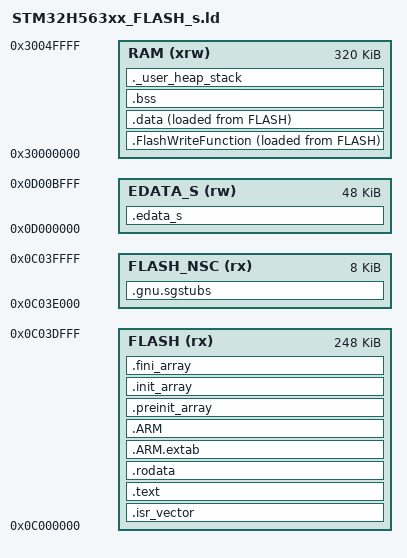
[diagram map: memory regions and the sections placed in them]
/*******************************************************************************
 **
 ** @file        : LinkerScript.ld
 **
 ** @author      : Auto-generated by STM32CubeIDE
 **
 ** @brief       : Linker script for STM32H563xx Device from STM32H5 series
 **                      2048Kbytes FLASH
 **                      640Kbytes RAM
 **
 **                Set heap size, stack size and stack location according
 **                to application requirements.
 **
 **                Set memory bank area and size if external memory is used
 **
 **  Target      : STMicroelectronics STM32
 **
 **  Distribution: The file is distributed as is, without any warranty
 **                of any kind.
 **
 ******************************************************************************
 ** @attention
 **
 ** Copyright (c) 2023 STMicroelectronics.
 ** All rights reserved.
 **
 ** This software is licensed under terms that can be found in the LICENSE file
 ** in the root directory of this software component.
 ** If no LICENSE file comes with this software, it is provided AS-IS.
 **
 ******************************************************************************
 */

/* Entry Point */
ENTRY(Reset_Handler)

/* Highest address of the user mode stack */
_estack = ORIGIN(RAM) + LENGTH(RAM);

_Min_Heap_Size  = 0x200;
_Min_Stack_Size = 0x400;

/* Memories definition */
MEMORY
{
  RAM      (xrw) : ORIGIN = 0x30000000, LENGTH = 320K

  /* Secure firmware code: Bank 1 sectors 0-30 (31 sectors x 8KB = 248KB) */
  FLASH    (rx)  : ORIGIN = 0x0C000000, LENGTH = 248K

  /* NSC veneer: Bank 1 sector 31 (8KB) */
  FLASH_NSC (rx) : ORIGIN = 0x0C03E000, LENGTH = 8K

  /* EDATA1: Bank 1 high-cycle data area (sectors 120-127, 8 sectors x 6KB = 48KB) */
  EDATA_S   (rw) : ORIGIN = 0x0D000000, LENGTH = 48K
}

/* Sections */
SECTIONS
{
  /* The startup code into "FLASH" Rom type memory */
  .isr_vector :
  {
    . = ALIGN(4);
    KEEP(*(.isr_vector))
    . = ALIGN(4);
  } >FLASH

  .FlashWriteFunction :
  {
    . = ALIGN(4);
    _sramfunc = .;

    application/bsp/stm/stm32h563/CMakeFiles/jerry_secure_app.dir/Drivers/STM32H5xx_HAL_Driver/Src/stm32h5xx_hal_flash.c.obj(.text*)
    application/bsp/stm/stm32h563/CMakeFiles/jerry_secure_app.dir/Drivers/STM32H5xx_HAL_Driver/Src/stm32h5xx_hal_flash_ex.c.obj(.text*)
    application/bsp/stm/stm32h563/CMakeFiles/jerry_secure_app.dir/Secure/Core/EEPROM_Emul/Core/eeprom_emul.c.obj(.text*)
    application/bsp/stm/stm32h563/CMakeFiles/jerry_secure_app.dir/Secure/Core/EEPROM_Emul/Porting/STM32H5/flash_interface.c.obj(.text*)

    . = ALIGN(4);
    _eramfunc = .;
  } >RAM AT> FLASH

  _siramfunc = LOADADDR(.FlashWriteFunction);

  /* The program code and other data into "FLASH" Rom type memory */
  .text :
  {
    . = ALIGN(4);
    *(.text)
    *(.text*)
    *(.glue_7)
    *(.glue_7t)
    *(.eh_frame)
    KEEP (*(.init))
    KEEP (*(.fini))
    . = ALIGN(4);
    _etext = .;
  } >FLASH

  /* Constant data into "FLASH" Rom type memory */
  .rodata :
  {
    . = ALIGN(4);
    *(.rodata)
    *(.rodata*)
    . = ALIGN(4);
  } >FLASH

  .ARM.extab :
  {
    . = ALIGN(4);
    *(.ARM.extab* .gnu.linkonce.armextab.*)
    . = ALIGN(4);
  } >FLASH

  .ARM :
  {
    . = ALIGN(4);
    __exidx_start = .;
    *(.ARM.exidx*)
    __exidx_end = .;
    . = ALIGN(4);
  } >FLASH

  .preinit_array :
  {
    . = ALIGN(4);
    PROVIDE_HIDDEN (__preinit_array_start = .);
    KEEP (*(.preinit_array*))
    PROVIDE_HIDDEN (__preinit_array_end = .);
    . = ALIGN(4);
  } >FLASH

  .init_array :
  {
    . = ALIGN(4);
    PROVIDE_HIDDEN (__init_array_start = .);
    KEEP (*(SORT(.init_array.*)))
    KEEP (*(.init_array*))
    PROVIDE_HIDDEN (__init_array_end = .);
    . = ALIGN(4);
  } >FLASH

  .fini_array :
  {
    . = ALIGN(4);
    PROVIDE_HIDDEN (__fini_array_start = .);
    KEEP (*(SORT(.fini_array.*)))
    KEEP (*(.fini_array*))
    PROVIDE_HIDDEN (__fini_array_end = .);
    . = ALIGN(4);
  } >FLASH

  /* Used by the startup to initialize data */
  _sidata = LOADADDR(.data);

  /* Initialized data sections into "RAM" Ram type memory */
  .data :
  {
    . = ALIGN(4);
    _sdata = .;
    *(.data)
    *(.data*)
    *(.RamFunc)
    *(.RamFunc*)
    . = ALIGN(4);
    _edata = .;
  } >RAM AT> FLASH

  /* Secure Gateway stubs */
  .gnu.sgstubs :
  {
    . = ALIGN(4);
    *(.gnu.sgstubs*)
    . = ALIGN(4);
  } >FLASH_NSC

  /* EDATA1 region — managed entirely by EEPROM emulation middleware at runtime */
  .edata_s (NOLOAD) :
  {
    . = ALIGN(16);
    __edata_s_start = .;
    . = . + LENGTH(EDATA_S);
    __edata_s_end = .;
  } >EDATA_S

  /* Uninitialized data section into "RAM" Ram type memory */
  . = ALIGN(4);
  .bss :
  {
    _sbss = .;
    __bss_start__ = _sbss;
    *(.bss)
    *(.bss*)
    *(COMMON)
    . = ALIGN(4);
    _ebss = .;
    __bss_end__ = _ebss;
  } >RAM

  /* User_heap_stack section */
  ._user_heap_stack :
  {
    . = ALIGN(8);
    PROVIDE ( end = . );
    PROVIDE ( _end = . );
    . = . + _Min_Heap_Size;
    . = . + _Min_Stack_Size;
    . = ALIGN(8);
  } >RAM

  /* Remove information from the compiler libraries */
  /DISCARD/ :
  {
    libc.a ( * )
    libm.a ( * )
    libgcc.a ( * )
  }

  .ARM.attributes 0 : { *(.ARM.attributes) }
}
